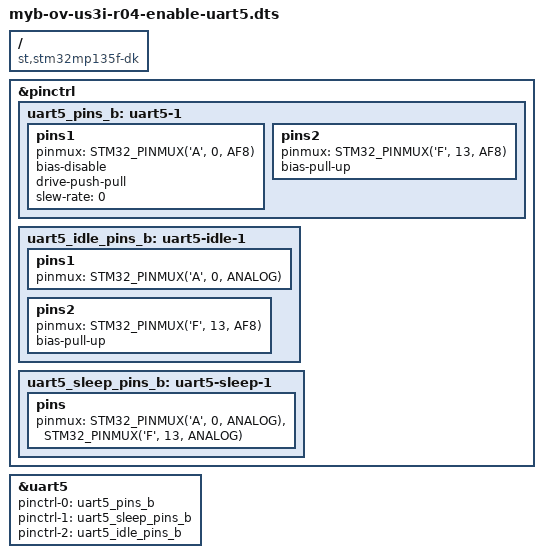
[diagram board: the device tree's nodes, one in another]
/dts-v1/;
/plugin/;

#include <dt-bindings/gpio/gpio.h>
#include <dt-bindings/pinctrl/stm32-pinfunc.h>

/ {
    compatible = "st,stm32mp135f-dk", "st,stm32mp135";

    fragment@0 {
        target = <&pinctrl>;
        __overlay__ {
            uart5_pins_b: uart5-1 {
                pins1 {
                    pinmux = <STM32_PINMUX('A', 0, AF8)>; /* UART5_TX */
                    bias-disable;
                    drive-push-pull;
                    slew-rate = <0>;
                };
                pins2 {
                    pinmux = <STM32_PINMUX('F', 13, AF8)>; /* UART5_RX */
                    bias-pull-up;
                };
            };

            uart5_idle_pins_b: uart5-idle-1 {
                pins1 {
                    pinmux = <STM32_PINMUX('A', 0, ANALOG)>; /* UART5_TX */
                };
                pins2 {
                    pinmux = <STM32_PINMUX('F', 13, AF8)>; /* UART5_RX */
                    bias-pull-up;
                };
            };

            uart5_sleep_pins_b: uart5-sleep-1 {
                pins {
                    pinmux = <STM32_PINMUX('A', 0, ANALOG)>, /* UART5_TX */
                        <STM32_PINMUX('F', 13, ANALOG)>; /* UART5_RX */
                };
            };
        };
    };

    fragment@1 {
        target = <&uart5>;
        __overlay__ {
            pinctrl-names = "default", "sleep", "idle";
            pinctrl-0 = <&uart5_pins_b>;
            pinctrl-1 = <&uart5_sleep_pins_b>;
            pinctrl-2 = <&uart5_idle_pins_b>;
            status = "okay";
        };
    };
};
